# STM32H7P5xx register map
File version: 1.0
Registers are 32-bit, read-write, reset 0x0 unless marked. A register's access mark holds for its fields unless they carry their own. Offsets are from the block's base; [hi:lo] are bit positions; {n}, {i} and the like mark numbered series; 'fields as' and 'values as' point back to an identical list.

## COMP1 — Comparator (COMP)
Base 0x58007000
Same registers: COMP2 0x58007200, COMP3 0x58007400, COMP4 0x58007600, COMP5 0x58007800, COMP6 0x58007A00, COMP7 0x58007C00, COMP8 0x58007E00
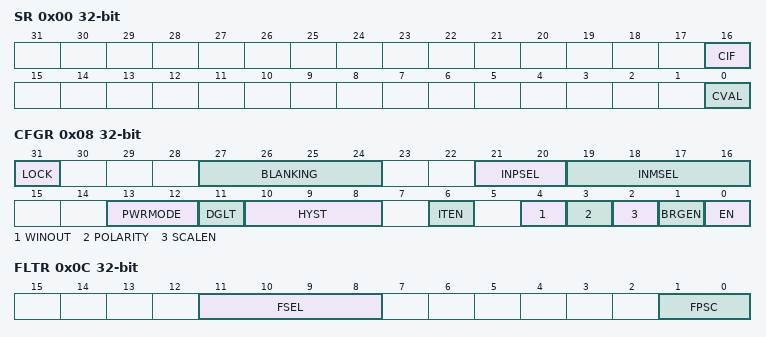
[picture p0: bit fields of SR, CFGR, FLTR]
0x00 SR ro — Comparator status register
  [16] CIF — COMP interrupt flag
  [0] CVAL — COMP output status bit
0x04 ICFR — Comparator interrupt clear flag register
  [16] CCIF — Clear COMP interrupt flag
0x08 CFGR — Comparator configuration register
  [31] LOCK — Lock bit
  [27:24] BLANKING — COMP channel blanking source selection bits
  [21:20] INPSEL — COMP channel non-inverting input selection bit
  [19:16] INMSEL — COMP channel inverting input selection field
  [13:12] PWRMODE — COMP power mode selector
  [11] DGLT — DEGLITCHER enable
  [10:8] HYST — COMP channel hysteresis selection bits
  [6] ITEN — COMP channel interrupt enable
  [4] WINOUT — COMP output selector
  [3] POLARITY — COMP polarity selection bit
  [2] SCALEN — Voltage scaler enable bit
  [1] BRGEN — Scaler bridge enable
  [0] EN — COMP channel enable bit
0x0C FLTR — Comparator filter configuration register
  [11:8] FSEL — COMP digital filter configuration selection
  [1:0] FPSC — COMP digital filter configuration selection

## COMP12_COMMON
Base 0x58007000; alternate view of COMP1
Same registers: COMP34_COMMON 0x58007400 (alternate view of COMP3), COMP56_COMMON 0x58007800 (alternate view of COMP5), COMP78_COMMON 0x58007C00 (alternate view of COMP7)
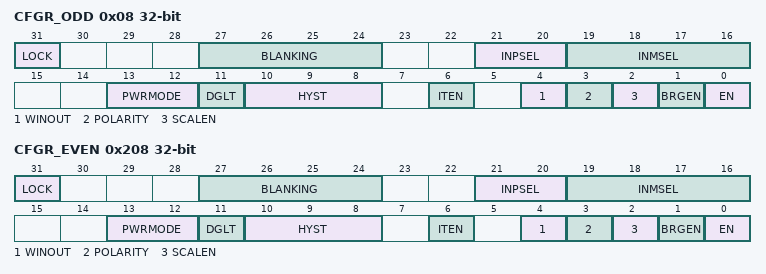
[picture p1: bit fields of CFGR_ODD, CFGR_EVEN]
0x08 CFGR_ODD — COMP config register located in register of comparator instance odd, used for bits common to several COMP instances
  [31] LOCK — Lock bit
  [27:24] BLANKING — COMP channel blanking source selection bits
  [21:20] INPSEL — COMP channel non-inverting input selection bit
  [19:16] INMSEL — COMP channel inverting input selection field
  [13:12] PWRMODE — COMP power mode selector
  [11] DGLT — DEGLITCHER enable
  [10:8] HYST — COMP channel hysteresis selection bits
  [6] ITEN — COMP channel interrupt enable
  [4] WINOUT — COMP output selector
  [3] POLARITY — COMP polarity selection bit
  [2] SCALEN — Voltage scaler enable bit
  [1] BRGEN — Scaler bridge enable
  [0] EN — COMP channel enable bit
0x208 CFGR_EVEN — COMP config register located in register of comparator instance odd, used for bits common to several COMP instances
  fields as CFGR_ODD

## GPIOA — General-purpose I/Os (GPIO)
Base 0x58020000
Same registers: GPIOB 0x58020400, GPIOC 0x58020800, GPIOD 0x58020C00, GPIOE 0x58021000, GPIOF 0x58021400, GPIOG 0x58021800, GPIOH 0x58021C00, GPIOI 0x58022000
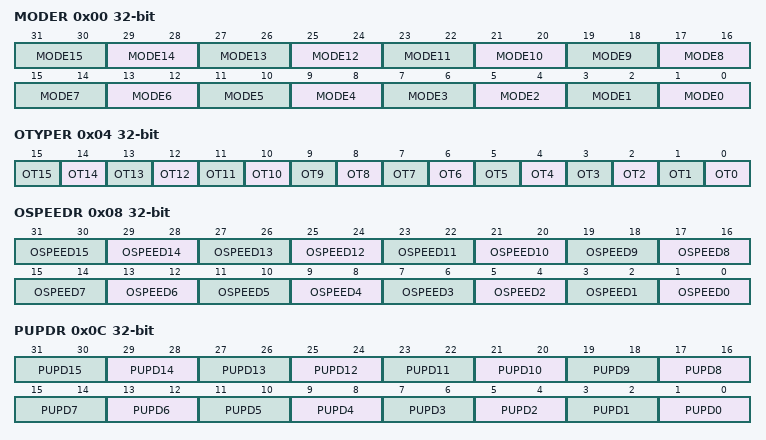
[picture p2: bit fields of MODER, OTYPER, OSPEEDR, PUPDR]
0x00 MODER — GPIO port mode register
  [2n+1:2n] MODE{n} (n=0..15) — Port x configuration I/O pin y
0x04 OTYPER — GPIO port output type register
  [n] OT{n} (n=0..15) — Port x configuration I/O pin y
0x08 OSPEEDR — GPIO port output speed register
  [2n+1:2n] OSPEED{n} (n=0..15) — Port x configuration I/O pin y
0x0C PUPDR — GPIO port pull-up/pull-down register
  [2n+1:2n] PUPD{n} (n=0..15) — Port x configuration I/O pin y
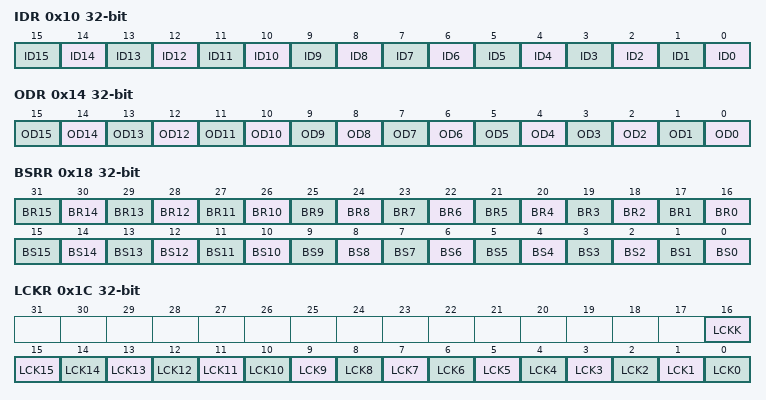
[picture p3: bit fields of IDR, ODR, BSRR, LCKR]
0x10 IDR ro — GPIO port input data register
  [n] ID{n} (n=0..15) — Port x input data I/O pin y
0x14 ODR — GPIO port output data register
  [n] OD{n} (n=0..15) — Port output data I/O pin y
0x18 BSRR — GPIO port bit set/reset register
  [n+16] BR{n} (n=0..15) — Port x reset I/O pin y
  [n] BS{n} (n=0..15) — Port x set I/O pin y
0x1C LCKR — GPIO port configuration lock register
  [16] LCKK — Lock key
  [n] LCK{n} (n=0..15) — Port x lock I/O pin y
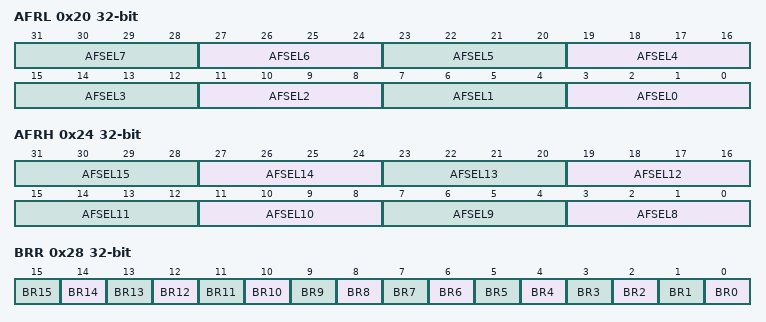
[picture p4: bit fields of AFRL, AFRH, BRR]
0x20 AFRL — GPIO alternate function low register
  [4n+3:4n] AFSEL{n} (n=0..7)
0x24 AFRH — GPIO alternate function low register
  [4n-29:4n-32] AFSEL{n} (n=8..15)
0x28 BRR — GPIO port bit reset register
  [n] BR{n} (n=0..15) — Port x reset IO pin y

## PWR — Power control (PWR)
Base 0x58024800
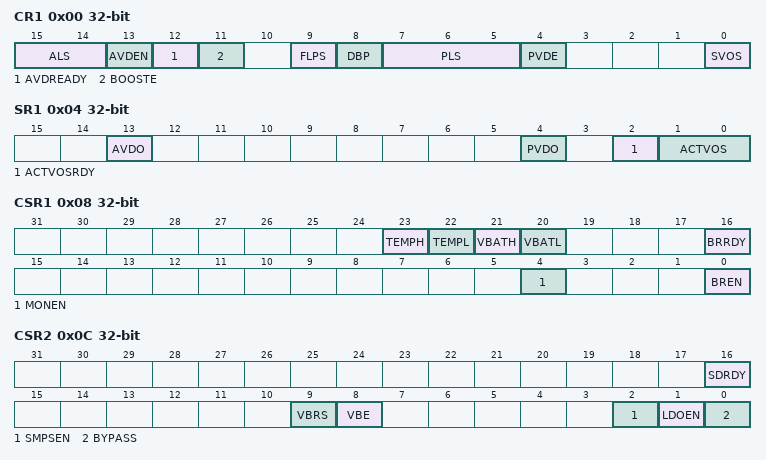
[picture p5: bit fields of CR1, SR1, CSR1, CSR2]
0x00 CR1 — PWR control register 1
  [15:14] ALS
  [13] AVDEN
  [12] AVDREADY — Analog voltage ready
  [11] BOOSTE — Analog switch VBoost control
  [9] FLPS — Flash low-power mode in Stop mode
  [8] DBP
  [7:5] PLS
  [4] PVDE
  [0] SVOS
0x04 SR1 ro — PWR status register 1
  [13] AVDO, [4] PVDO, [2] ACTVOSRDY, [1:0] ACTVOS
0x08 CSR1 — PWR control status register 1
  [23] TEMPH
  [22] TEMPL
  [21] VBATH
  [20] VBATL
  [16] BRRDY — Backup regulator ready
  [4] MONEN
  [0] BREN — Backup regulator enable
0x0C CSR2 — PWR control status register 2
  [16] SDRDY
  [9] VBRS
  [8] VBE — VBAT charging enable
  [2] SMPSEN
  [1] LDOEN
  [0] BYPASS — Power management unit bypass
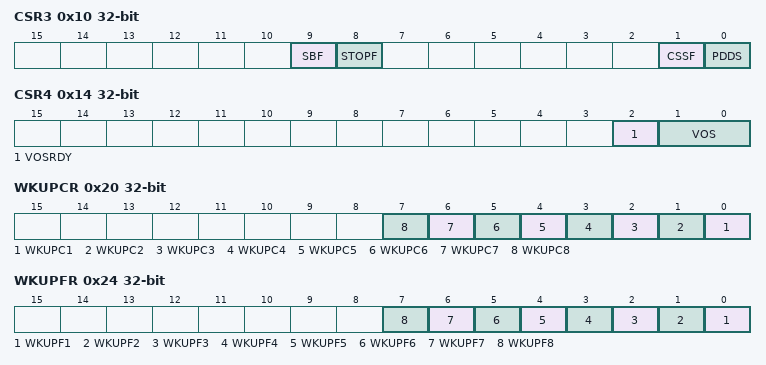
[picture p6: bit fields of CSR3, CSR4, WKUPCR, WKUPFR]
0x10 CSR3 — PWR CPU control status register 3
  [9] SBF — System Standby flag
  [8] STOPF — Stop flag
  [1] CSSF
  [0] PDDS — Power-down Deepsleep
0x14 CSR4 — PWR control status register 4
  [2] VOSRDY, [1:0] VOS
0x20 WKUPCR — PWR wakeup clear register
  [n-1] WKUPC{n} (n=1..8) — Clear wakeup pin flag for WKUP{n}
0x24 WKUPFR ro — PWR wakeup flag register
  [n-1] WKUPF{n} (n=1..8) — Wakeup pin WKUP{n} flag
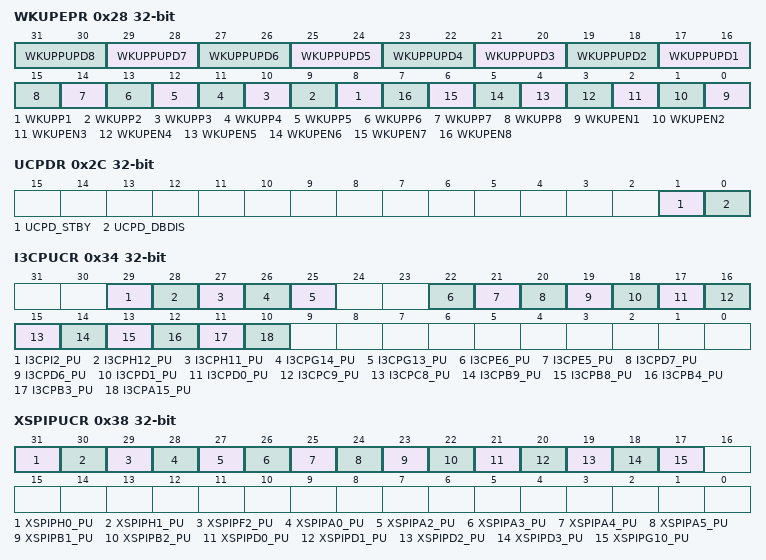
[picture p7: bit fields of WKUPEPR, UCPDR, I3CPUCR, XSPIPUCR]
0x28 WKUPEPR — PWR wakeup enable and polarity register
  [2n+15:2n+14] WKUPPUPD{n} (n=1..8)
  [n+7] WKUPP{n} (n=1..8) — Wakeup pin polarity bit for WKUPn
  [n-1] WKUPEN{n} (n=1..8) — Enable wakeup pin WKUPn
0x2C UCPDR — PWR USB Type-C and power delivery register
  [1] UCPD_STBY — UCPD Standby mode
  [0] UCPD_DBDIS — UCPD dead battery disable
0x30 APCR — PWR apply pull register
  [0] APC
0x34 I3CPUCR — PWR I3C pull-up control register
  [29] I3CPI2_PU — Port PI2 I3C pull-up bit
  [28] I3CPH12_PU — Port PH12 I3C pull-up bit
  [27] I3CPH11_PU — Port PH11 I3C pull-up bit
  [26] I3CPG14_PU — Port PG14 I3C pull-up bit
  [25] I3CPG13_PU — Port PG13 I3C pull-up bit
  [22] I3CPE6_PU — Port PE6 I3C pull-up bit
  [21] I3CPE5_PU — Port PE5 I3C pull-up bit
  [20] I3CPD7_PU — Port PD7 I3C pull-up bit
  [19] I3CPD6_PU — Port PD6 I3C pull-up bit
  [18] I3CPD1_PU — Port PD1 I3C pull-up bit
  [17] I3CPD0_PU — Port PD0 I3C pull-up bit
  [16] I3CPC9_PU — Port PC9 I3C pull-up bit
  [15] I3CPC8_PU — Port PC8 I3C pull-up bit
  [14] I3CPB9_PU — Port PB9 I3C pull-up bit
  [13] I3CPB8_PU — Port PB8 I3C pull-up bit
  [12] I3CPB4_PU — Port PB4 I3C pull-up bit
  [11] I3CPB3_PU — Port PB3 I3C pull-up bit
  [10] I3CPA15_PU — Port PA15 I3C pull-up bit
0x38 XSPIPUCR — PWR XSPI pull-up control register
  [31] XSPIPH0_PU — Port PH0 XSPI pull-up bit
  [30] XSPIPH1_PU — Port PH1 XSPI pull-up bit
  [29] XSPIPF2_PU — Port PF2 XSPI pull-up bit
  [28] XSPIPA0_PU — Port PA0 XSPI pull-up bit
  [29-n] XSPIPA{n}_PU (n=2..5) — Port PA{n} XSPI pull-up bit
  [23] XSPIPB1_PU — Port PB1 XSPI pull-up bit
  [22] XSPIPB2_PU — Port PB2 XSPI pull-up bit
  [21-n] XSPIPD{n}_PU (n=0..3) — Port PD{n} XSPI pull-up bit
  [17] XSPIPG10_PU — Port PG10 XSPI pull-up bit
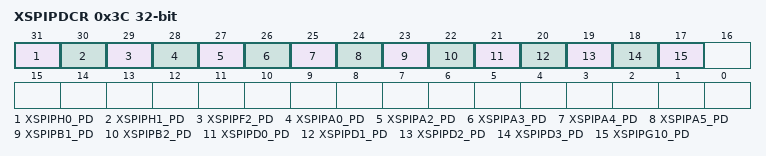
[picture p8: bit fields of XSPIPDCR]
0x3C XSPIPDCR — PWR XSPI pull-down control register
  [31] XSPIPH0_PD — Port PH0 XSPI pull-down bit
  [30] XSPIPH1_PD — Port PH1 XSPI pull-down bit
  [29] XSPIPF2_PD — Port PF2 XSPI pull-down bit
  [28] XSPIPA0_PD — Port PA0 XSPI pull-down bit
  [29-n] XSPIPA{n}_PD (n=2..5) — Port PA{n} XSPI pull-down bit
  [23] XSPIPB1_PD — Port PB1 XSPI pull-down bit
  [22] XSPIPB2_PD — Port PB2 XSPI pull-down bit
  [21-n] XSPIPD{n}_PD (n=0..3) — Port PD{n} XSPI pull-down bit
  [17] XSPIPG10_PD — Port PG10 XSPI pull-down bit
